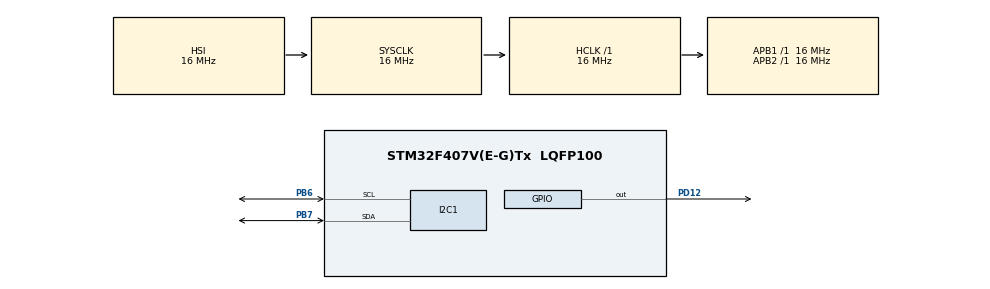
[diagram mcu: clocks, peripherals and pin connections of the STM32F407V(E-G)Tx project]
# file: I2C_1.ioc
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Mcu.Family=STM32F4
Mcu.Name=STM32F407V(E-G)Tx
Mcu.Package=LQFP100
NVIC.PriorityGroup=NVIC_PRIORITYGROUP_4
PB6.Mode=I2C
PB6.Signal=I2C1_SCL
PB7.Mode=I2C
PB7.Signal=I2C1_SDA
PD12.Signal=GPIO_Output
ProjectManager.HeapSize=0x200
ProjectManager.StackSize=0x400
ProjectManager.TargetToolchain=STM32CubeIDE
RCC.AHBFreq_Value=16000000
RCC.APB1Freq_Value=16000000
RCC.APB2Freq_Value=16000000
RCC.CortexFreq_Value=16000000
RCC.HSE_VALUE=25000000
RCC.HSI_VALUE=16000000
RCC.LSE_VALUE=32768
RCC.SYSCLKFreq_VALUE=16000000
RCC.VCOOutputFreq_Value=192000000
board=custom

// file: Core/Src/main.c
/* USER CODE BEGIN Header */
/**
  ******************************************************************************
  * @file           : main.c
  * @brief          : Main program body
  ******************************************************************************
  * @attention
  *
  * <h2><center>&copy; Copyright (c) 2021 STMicroelectronics.
  * All rights reserved.</center></h2>
  *
  * This software component is licensed by ST under BSD 3-Clause license,
  * the "License"; You may not use this file except in compliance with the
  * License. You may obtain a copy of the License at:
  *                        opensource.org/licenses/BSD-3-Clause
  *
  ******************************************************************************
  */
/* USER CODE END Header */
#include "main.h"

I2C_HandleTypeDef hi2c1;

/* USER CODE BEGIN PV */

//slave address (slave device) located and defined here
#define i2cSlaveAddress 0xD0

/* USER CODE END PV */

void SystemClock_Config(void);
static void MX_GPIO_Init(void);
static void MX_I2C1_Init(void);

/* USER CODE BEGIN 0 */
//data buffer to send data
uint8_t i2cBuf[8]; // later read 6 byte at a time, normally only 2 (for reg address + return data)

int16_t ax,ay,az ; // axis
float XaccelVal, YaccelVal, ZaccelVal; //

/* USER CODE END 0 */

int main(void)
{

  /* MCU Configuration--------------------------------------------------------*/

  /* Reset of all peripherals, Initializes the Flash interface and the Systick. */
  HAL_Init();

  /* Configure the system clock */
  SystemClock_Config();

  /* Initialize all configured peripherals */
  MX_GPIO_Init();
  MX_I2C1_Init();
  /* USER CODE BEGIN 2 */

  //1. Scan the I2C addresses (all 8 bit (255)) - (slave device's address)
  for(uint8_t i=0; i<255;i++)
  {
	  //test for address 0 to 255 (so i), try 1 time, 10ms timeout, OK if slave add found
	  if(HAL_I2C_IsDeviceReady(&hi2c1, i, 1, 10) == HAL_OK)
	  {
		  HAL_GPIO_TogglePin(GPIOD, GPIO_PIN_12); //toggle led if slave address 'i' value found
		  //go debugging and watch 'i' to see its value, put breakpoint at LED toggle line (i value got )
		  //usually is = to 0xD0 found in debug mode, define slave address (slave device) at top
		  break;
	  }
  }
  /******* I2C write *********/
  //WRITE to slave device, write to reg 28 to set accelerometer range
  //1. set reg address for 1st byte of data buffer
  i2cBuf[0] = 28;
  //2. data write to i2c (data write to the reg)
  i2cBuf[1] = 0x08; //to set range +/-4g for acceleometer
  //3. transmit i2c data
  HAL_I2C_Master_Transmit(&hi2c1,i2cSlaveAddress ,i2cBuf,2 , 10 ); //send 2 bytes, reg add + data , 10ms timeout

  /******* I2C READ *********/
  // read from reg 28 - see if data 0x08 written
  //1. Transmit in its own reg 28 first
  i2cBuf[0] = 28;
  HAL_I2C_Master_Transmit(&hi2c1,i2cSlaveAddress ,i2cBuf, 1 , 10 ); //send 1 bytes
  //read data
  i2cBuf[1] = 0x00; //set to 0 before read as needed to store read data
  HAL_I2C_Master_Receive(&hi2c1, i2cSlaveAddress, i2cBuf[1], 1, 10); //store in [1], read only 1 byte , 10ms
  //expect to receive 0x08 as we wrote this initially

  /* USER CODE END 2 */

  /* Infinite loop */
  while (1)
  {

    /* USER CODE BEGIN 3 */
	/******* READ Accelerometer DATA *********/
	//1. Transmit in its own reg 0x3B first
	i2cBuf[0] = 0x3B; // reg address for X_Axis H (high)
	HAL_I2C_Master_Transmit(&hi2c1,i2cSlaveAddress ,i2cBuf, 1 , 10 ); //send 1 bytes
	//read data
	i2cBuf[1] = 0x00; //set to 0 before read as needed to store read data
	//store in [1],reads 6 bytes (RAW data for X,Y,Z H/L - each axis got 2 bytes)
	HAL_I2C_Master_Receive(&hi2c1, i2cSlaveAddress, i2cBuf[1], 6, 10);
	// convert raw data to in units for gravity 'g' define the variables above main
	// each axis has 2 bytes (high/low - accel datasheet)
	//combine (OR) the 2 bytes of that axis into 16bit data (raw x-axis data) -(e.g ax defined above main)

	ax = -(i2cBuf[1]<<8 | i2cBuf[2]);
	ay = -(i2cBuf[3]<<8 | i2cBuf[4]);
	az = (i2cBuf[5]<<8 | i2cBuf[6]);

	//make in 'g' units of gravity
	XaccelVal = ax/8192.0;
	YaccelVal = ay/8192.0;
	ZaccelVal = az/8192.0;

  }
  /* USER CODE END 3 */
}

void SystemClock_Config(void)
{
  RCC_OscInitTypeDef RCC_OscInitStruct = {0};
  RCC_ClkInitTypeDef RCC_ClkInitStruct = {0};

  /** Configure the main internal regulator output voltage
  */
  __HAL_RCC_PWR_CLK_ENABLE();
  __HAL_PWR_VOLTAGESCALING_CONFIG(PWR_REGULATOR_VOLTAGE_SCALE1);
  /** Initializes the RCC Oscillators according to the specified parameters
  * in the RCC_OscInitTypeDef structure.
  */
  RCC_OscInitStruct.OscillatorType = RCC_OSCILLATORTYPE_HSI;
  RCC_OscInitStruct.HSIState = RCC_HSI_ON;
  RCC_OscInitStruct.HSICalibrationValue = RCC_HSICALIBRATION_DEFAULT;
  RCC_OscInitStruct.PLL.PLLState = RCC_PLL_NONE;
  if (HAL_RCC_OscConfig(&RCC_OscInitStruct) != HAL_OK)
  {
    Error_Handler();
  }
  /** Initializes the CPU, AHB and APB buses clocks
  */
  RCC_ClkInitStruct.ClockType = RCC_CLOCKTYPE_HCLK|RCC_CLOCKTYPE_SYSCLK
                              |RCC_CLOCKTYPE_PCLK1|RCC_CLOCKTYPE_PCLK2;
  RCC_ClkInitStruct.SYSCLKSource = RCC_SYSCLKSOURCE_HSI;
  RCC_ClkInitStruct.AHBCLKDivider = RCC_SYSCLK_DIV1;
  RCC_ClkInitStruct.APB1CLKDivider = RCC_HCLK_DIV1;
  RCC_ClkInitStruct.APB2CLKDivider = RCC_HCLK_DIV1;

  if (HAL_RCC_ClockConfig(&RCC_ClkInitStruct, FLASH_LATENCY_0) != HAL_OK)
  {
    Error_Handler();
  }
}

static void MX_I2C1_Init(void)
{

  hi2c1.Instance = I2C1;
  hi2c1.Init.ClockSpeed = 100000;
  hi2c1.Init.DutyCycle = I2C_DUTYCYCLE_2;
  hi2c1.Init.OwnAddress1 = 0;
  hi2c1.Init.AddressingMode = I2C_ADDRESSINGMODE_7BIT;
  hi2c1.Init.DualAddressMode = I2C_DUALADDRESS_DISABLE;
  hi2c1.Init.OwnAddress2 = 0;
  hi2c1.Init.GeneralCallMode = I2C_GENERALCALL_DISABLE;
  hi2c1.Init.NoStretchMode = I2C_NOSTRETCH_DISABLE;
  if (HAL_I2C_Init(&hi2c1) != HAL_OK)
  {
    Error_Handler();
  }

}

static void MX_GPIO_Init(void)
{
  GPIO_InitTypeDef GPIO_InitStruct = {0};

  /* GPIO Ports Clock Enable */
  __HAL_RCC_GPIOD_CLK_ENABLE();
  __HAL_RCC_GPIOB_CLK_ENABLE();

  /*Configure GPIO pin Output Level */
  HAL_GPIO_WritePin(GPIOD, GPIO_PIN_12, GPIO_PIN_RESET);

  /*Configure GPIO pin : PD12 */
  GPIO_InitStruct.Pin = GPIO_PIN_12;
  GPIO_InitStruct.Mode = GPIO_MODE_OUTPUT_PP;
  GPIO_InitStruct.Pull = GPIO_NOPULL;
  GPIO_InitStruct.Speed = GPIO_SPEED_FREQ_LOW;
  HAL_GPIO_Init(GPIOD, &GPIO_InitStruct);

}

void Error_Handler(void)
{
  __disable_irq();
  while (1)
  {
  }
}

/************************ (C) COPYRIGHT STMicroelectronics *****END OF FILE****/
